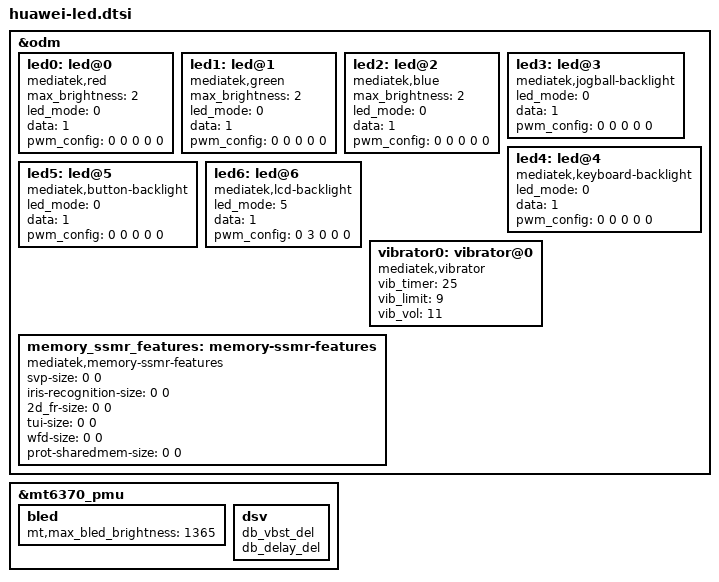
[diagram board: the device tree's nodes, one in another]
&odm {
	led0:led@0 {
		compatible = "mediatek,red";
		max_brightness = <2>;
		led_mode = <0>;
		data = <1>;
		pwm_config = <0 0 0 0 0>;
	};
	led1:led@1 {
		compatible = "mediatek,green";
		max_brightness = <2>;
		led_mode = <0>;
		data = <1>;
		pwm_config = <0 0 0 0 0>;
	};
	led2:led@2 {
		compatible = "mediatek,blue";
		max_brightness = <2>;
		led_mode = <0>;
		data = <1>;
		pwm_config = <0 0 0 0 0>;
	};
	led3:led@3 {
		compatible = "mediatek,jogball-backlight";
		led_mode = <0>;
		data = <1>;
		pwm_config = <0 0 0 0 0>;
	};
	led4:led@4 {
		compatible = "mediatek,keyboard-backlight";
		led_mode = <0>;
		data = <1>;
		pwm_config = <0 0 0 0 0>;
	};
	led5:led@5 {
		compatible = "mediatek,button-backlight";
		led_mode = <0>;
		data = <1>;
		pwm_config = <0 0 0 0 0>;
	};
	led6:led@6 {
		compatible = "mediatek,lcd-backlight";
		led_mode = <5>;
		data = <1>;
		pwm_config = <0 3 0 0 0>;
	};
	vibrator0:vibrator@0 {
		compatible = "mediatek,vibrator";
		vib_timer = <25>;
		vib_limit = <9>;
		vib_vol= <11>;
	};
	memory_ssmr_features: memory-ssmr-features {
		compatible = "mediatek,memory-ssmr-features";
		svp-size = <0 0>;
		iris-recognition-size = <0 0>;
		2d_fr-size = <0 0>;
		tui-size = <0 0>;
		wfd-size = <0 0>;
		prot-sharedmem-size = <0 0>;
	};
};
&mt6370_pmu {
			bled {
				mt,max_bled_brightness = <1365>;
			};
			dsv {
				db_vbst_del;
				db_delay_del;
			};
};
